# CY8C5888LTI_LP097 register map
File version: 0.1
CY8C58LP
Registers are 8-bit, read-write, no defined reset value unless marked. A register's access mark holds for its fields unless they carry their own. Offsets are from the block's base; lines under a group give offsets from that group; [hi:lo] are bit positions; {n}, {i} and the like mark numbered series; 'fields as' and 'values as' point back to an identical list; <NAME> marks a mode.

## Memory map
0x00000000 PWM_1
0x00000000 PWM_2
0x00000000 Control_Reg_4
0x00000000 Control_Reg_3
0x00000000 Timer_1
0x00000000 Control_Reg_1
0x00000000 Control_Reg_5
0x00000000 Control_Reg_6
0x00000000 UART
0x00000000 Control_Reg_2

## PWM_1
Base 0x00000000
0x4000642D PWM_1_COMPARE_Reg_ — UDB.D0 - Assigned Compare Value
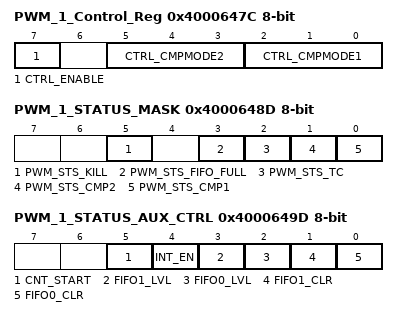
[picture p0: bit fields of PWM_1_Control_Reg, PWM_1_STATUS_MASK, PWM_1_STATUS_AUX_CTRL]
0x4000647C PWM_1_Control_Reg — UDB Control Register - Assigned Control Register Value
  [7] CTRL_ENABLE — Enable the PWM
  [5:3] CTRL_CMPMODE2 — Compare mode 2
  [2:0] CTRL_CMPMODE1 — Compare mode 1
0x4000648D PWM_1_STATUS_MASK — UDB Status bits Interrupt Mask Enable Register
  [5] PWM_STS_KILL ro — Enables the Interrupt on Kill
  [3] PWM_STS_FIFO_FULL ro — FIFO Full Status Mask
  [2] PWM_STS_TC ro — Enables the Interrupt on Terminal Count
  [1] PWM_STS_CMP2 ro — Enables the Interrupt on Compare 2
  [0] PWM_STS_CMP1 ro — Enables the Interrupt on Compare 1
0x4000649D PWM_1_STATUS_AUX_CTRL — UDB Auxilliary Control Register
  [5] CNT_START — FIFO0 clear
    0=E_CNT_START0 (Disable counter); 1=E_CNT_START1 (Enable counter)
  [4] INT_EN
    0=E_INT_EN0 (Interrupt disabled); 1=E_INT_EN1 (Interrupt enabled)
  [3] FIFO1_LVL — FIFO level
    0=E_FIFO_LVL_0 (FIFO LVL: input mode: FIFO not full; output mode: FIFO not empty); 1=E_FIFO_LVL_1 (FIFO LVL: input mode: FIFO at least 1/2 empty; output mode: FIFO at least 1/2 full)
  [2] FIFO0_LVL — FIFO level
    values as FIFO1_LVL
  [1] FIFO1_CLR — FIFO1 clear
    0=E_FIFO_CLR_0 (Normal FIFO operation); 1=E_FIFO_CLR_1 (Clear FIFO state)
  [0] FIFO0_CLR — FIFO0 clear
    values as FIFO1_CLR

## PWM_2
Base 0x00000000
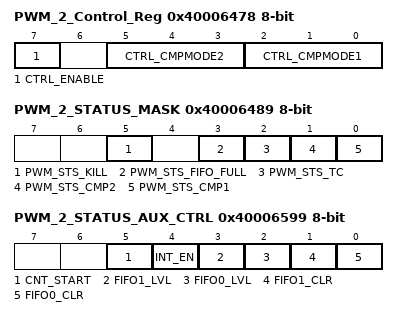
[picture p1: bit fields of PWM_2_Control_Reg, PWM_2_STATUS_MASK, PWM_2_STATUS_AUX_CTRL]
0x40006478 PWM_2_Control_Reg — UDB Control Register - Assigned Control Register Value
  [7] CTRL_ENABLE — Enable the PWM
  [5:3] CTRL_CMPMODE2 — Compare mode 2
  [2:0] CTRL_CMPMODE1 — Compare mode 1
0x40006489 PWM_2_STATUS_MASK — UDB Status bits Interrupt Mask Enable Register
  fields as PWM_1.PWM_1_STATUS_MASK
0x40006529 PWM_2_COMPARE_Reg_ — UDB.D0 - Assigned Compare Value
0x40006599 PWM_2_STATUS_AUX_CTRL — UDB Auxilliary Control Register
  fields as PWM_1.PWM_1_STATUS_AUX_CTRL

## Control_Reg_4
Base 0x00000000
0x4000647B Control_Reg_4_CONTROL_REG

## Control_Reg_3
Base 0x00000000
0x40006479 Control_Reg_3_CONTROL_REG

## Timer_1
Base 0x00000000
0x400043A3 Timer_1_GLOBAL_ENABLE — PM.ACT.CFG
  [3:0] en_timer — Enable timer/counters.
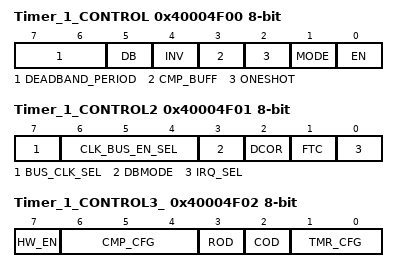
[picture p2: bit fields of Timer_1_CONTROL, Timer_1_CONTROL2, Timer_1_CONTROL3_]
0x40004F00 Timer_1_CONTROL — TMRx.CFG0
  [7:6] DEADBAND_PERIOD
  [5] DB — Deadband mode--Deadband phases phi1 and phi2 are outputted on CMP and TC output pins respectively.
    0=Timer (CMP and TC are output.); 1=Deadband (PHI1 (instead of CMP) and PHI2 (instead of TC) are output.)
  [4] INV — Invert sense of TIMEREN signal
  [3] CMP_BUFF — Buffer compare register. Compare register updates only on timer terminal count.
  [2] ONESHOT — Timer stops upon reaching stop condition defined by TMR_CFG bits. Can be restarted by asserting TIMER RESET or disabling and re-enabling block.
  [1] MODE — Mode. (0 = Timer; 1 = Comparator)
    0=Timer mode. CNT/CMP register holds timer count value.; 1=Comparator mode. CNT/CMP register holds comparator threshold value.
  [0] EN — Enables timer/comparator.
0x40004F01 Timer_1_CONTROL2 — TMRx.CFG1
  [7] BUS_CLK_SEL — Bus Clock selection.
  [6:4] CLK_BUS_EN_SEL — Digital Global Clock selection.
  [3] DBMODE — Deadband mode (asynchronous/synchronous). CMP output pin is also affected when not in deadband mode (CFG0.DEADBAND).
  [2] DCOR — Disable Clear on Read (DCOR) of Status Register SR0.
  [1] FTC — First Terminal Count (FTC). Setting this bit forces a single pulse on the TC pin when first enabled.
    0=Disable_FTC (Disable the single cycle pulse, which signifies the timer is starting.); 1=Enable_FTC (Enable the single cycle pulse, which signifies the timer is starting.)
  [0] IRQ_SEL — Irq selection. (0 = raw interrupts; 1 = status register interrupts)
0x40004F02 Timer_1_CONTROL3_ — TMRx.CFG2
  [7] HW_EN — When set Timer Enable controls counting.
  [6:4] CMP_CFG — Comparator configurations
    0=Equal (Compare Equal); 1=Less_than (Compare Less Than); 2=Less_than_or_equal (Compare Less Than or Equal .); 3=Greater (Compare Greater Than .); 4=Greater_than_or_equal (Compare Greater Than or Equal)
  [3] ROD — Reset On Disable (ROD). Resets internal state of output logic
  [2] COD — Clear On Disable (COD). Clears or gates outputs to zero.
  [1:0] TMR_CFG — Timer configuration (MODE = 0): 000 = Continuous; 001 = Pulsewidth; 010 = Period; 011 = Stop on IRQ
    0=Continuous (Timer runs while EN bit of CFG0 register is set to '1'.); 1=Pulsewidth (Timer runs from positive to negative edge of TIMEREN.); 2=Period (Timer runs from positive to positive edge of TIMEREN.); 3=Irq (Timer runs until IRQ.)
0x40004F04 Timer_1_PERIOD 16-bit — TMRx.PER0 - Assigned Period
0x40004F06 Timer_1_COUNTER 16-bit — TMRx.CNT_CMP0 - Current Down Counter Value

## Control_Reg_1
Base 0x00000000
0x40006579 Control_Reg_1_CONTROL_REG

## Control_Reg_5
Base 0x00000000
0x4000647D Control_Reg_5_CONTROL_REG

## Control_Reg_6
Base 0x00000000
0x40006578 Control_Reg_6_CONTROL_REG

## UART
Base 0x00000000
0x4000644A TX_UART_TX_DATA — TX Data Register
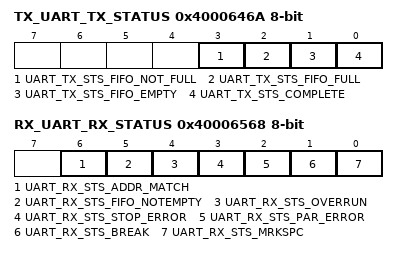
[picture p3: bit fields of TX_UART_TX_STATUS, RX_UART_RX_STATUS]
0x4000646A TX_UART_TX_STATUS — TX status register
  [3] UART_TX_STS_FIFO_NOT_FULL ro, [2] UART_TX_STS_FIFO_FULL ro, [1] UART_TX_STS_FIFO_EMPTY ro, [0] UART_TX_STS_COMPLETE ro
0x40006528 RX_UART_RX_ADDRESS1 — RX Address1 Register
0x40006538 RX_UART_RX_ADDRESS2 — RX Address2 Register
0x40006548 RX_UART_RX_DATA — RX Data Register
0x40006568 RX_UART_RX_STATUS — RX status register
  [6] UART_RX_STS_ADDR_MATCH ro, [5] UART_RX_STS_FIFO_NOTEMPTY ro, [4] UART_RX_STS_OVERRUN ro, [3] UART_RX_STS_STOP_ERROR ro, [2] UART_RX_STS_PAR_ERROR ro, [1] UART_RX_STS_BREAK ro, [0] UART_RX_STS_MRKSPC ro

## Control_Reg_2
Base 0x00000000
0x4000647A Control_Reg_2_CONTROL_REG
